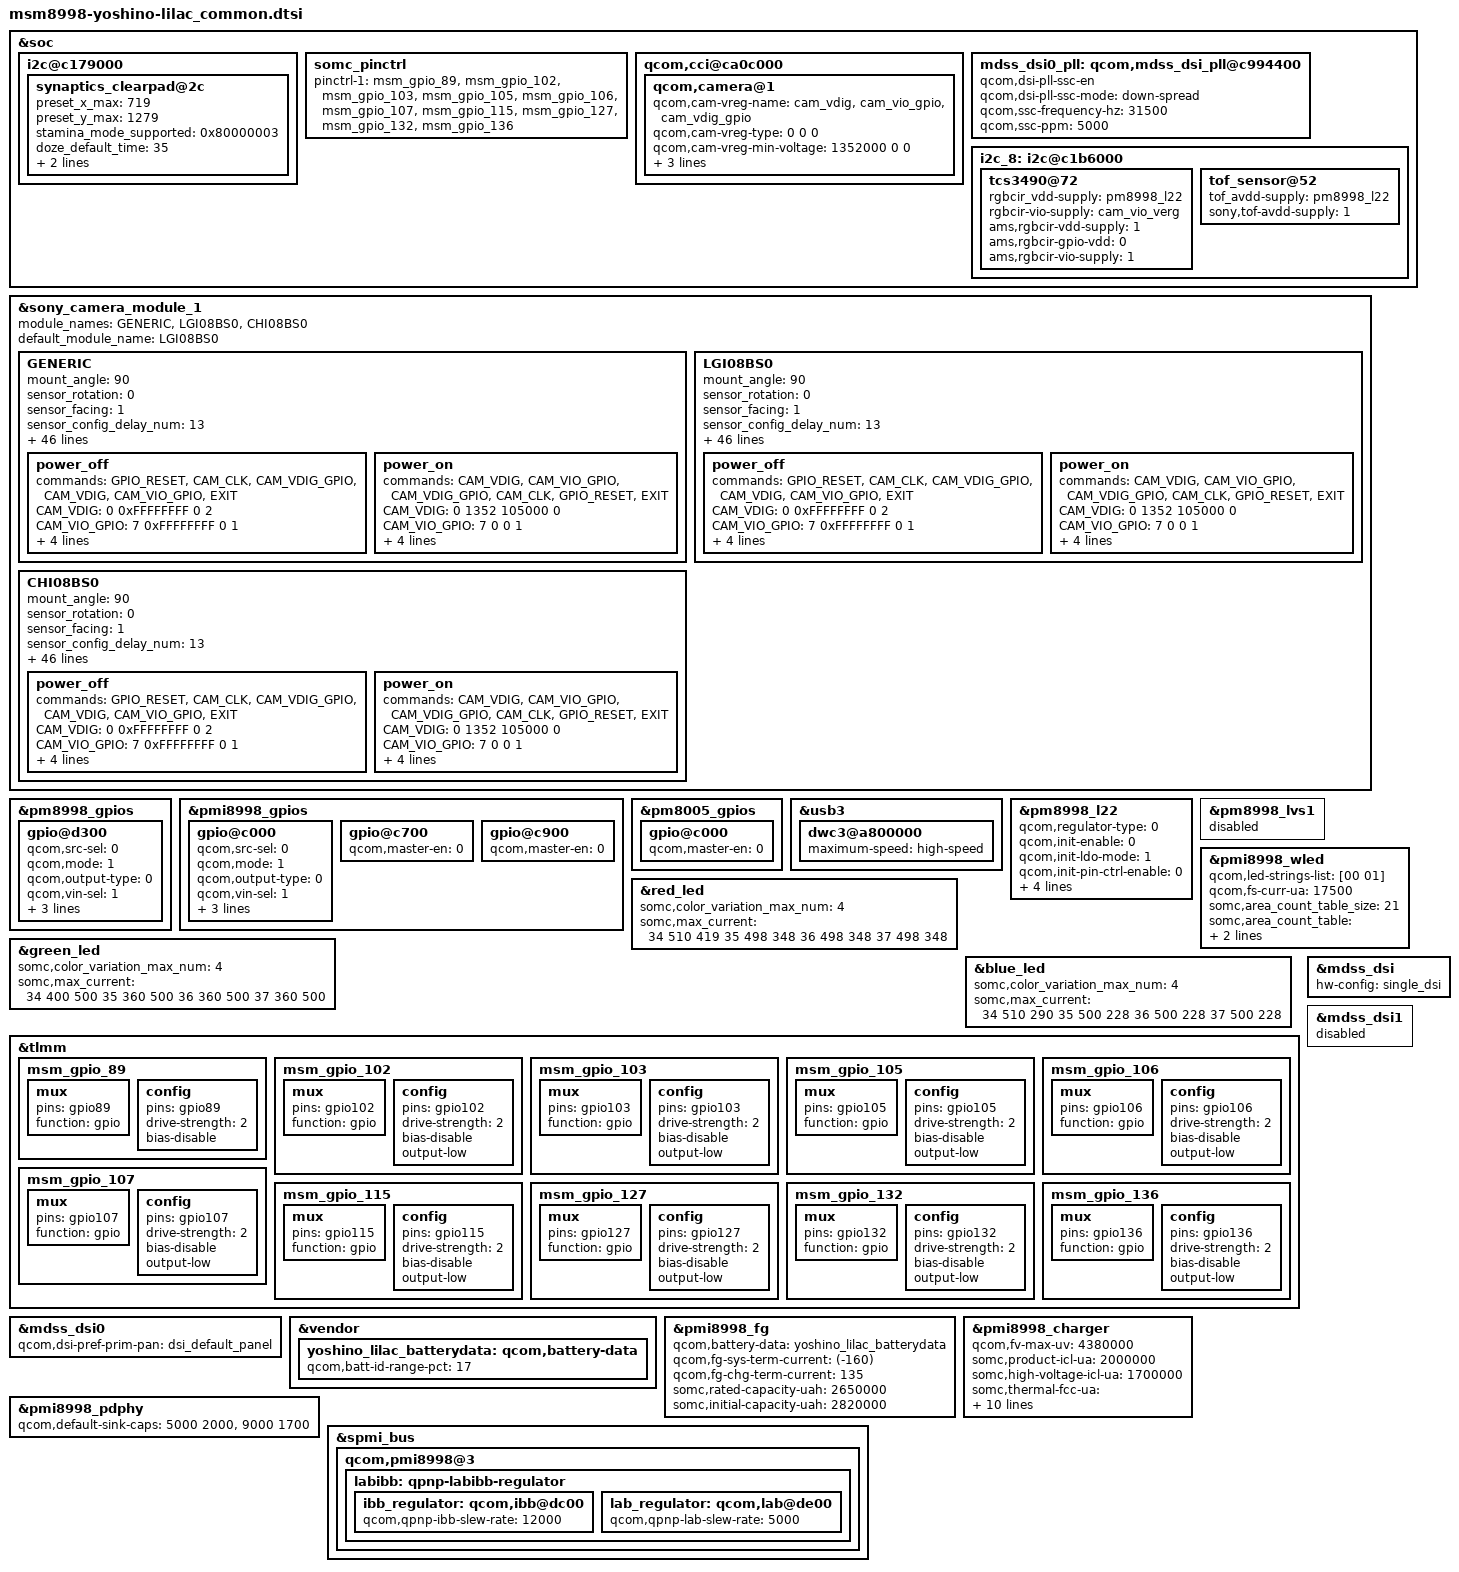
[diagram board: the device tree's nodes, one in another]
/* arch/arm64/boot/dts/qcom/msm8998-lilac_common.dtsi
 *
 * This program is free software; you can redistribute it and/or modify
 * it under the terms of the GNU General Public License version 2 and
 * only version 2 as published by the Free Software Foundation.
 *
 * This program is distributed in the hope that it will be useful,
 * but WITHOUT ANY WARRANTY; without even the implied warranty of
 * MERCHANTABILITY or FITNESS FOR A PARTICULAR PURPOSE.  See the
 * GNU General Public License for more details.
 */
/*
 * Copyright (C) 2016 Sony Mobile Communications Inc.
 *
 * This program is free software; you can redistribute it and/or modify
 * it under the terms of the GNU General Public License version 2, as
 * published by the Free Software Foundation.
 */

#include "msm8998-yoshino-common.dtsi"
#include "dsi-panel-lilac.dtsi"

&soc {
	/* I2C: BLSP5 */
	i2c@c179000 { /* BLSP1 QUP5 */
		synaptics_clearpad@2c {
			preset_x_max = <719>;
			preset_y_max = <1279>;

			/* Stamina Mode */
			stamina_mode_supported = <0x80000003>;

			/* F01_RMI_CTRL05: Doze Holdoff */
			doze_default_time = <35>;
			doze_glove_mode_time = <35>;
			doze_cover_mode_time = <35>;
		};
	};

	somc_pinctrl: somc_pinctrl {
		pinctrl-1 = <&msm_gpio_89 &msm_gpio_102 &msm_gpio_103 &msm_gpio_105 &msm_gpio_106
			     &msm_gpio_107 &msm_gpio_115 &msm_gpio_127 &msm_gpio_132 &msm_gpio_136>;
	};

	qcom,cci@ca0c000 {
		qcom,camera@1 {
			/delete-property/ cam_vio-supply;
			/delete-property/ cam_vaf-supply;
			qcom,cam-vreg-name = "cam_vdig", "cam_vio_gpio", "cam_vdig_gpio";
			qcom,cam-vreg-type = <0 0 0>;
			qcom,cam-vreg-min-voltage = <1352000 0 0>;
			qcom,cam-vreg-max-voltage = <1352000 0 0>;
			qcom,cam-vreg-op-mode = <105000 0 0>;
			sony,eeprom_type = <2>;
		};
	};

	mdss_dsi0_pll: qcom,mdss_dsi_pll@c994400 {
		qcom,dsi-pll-ssc-en;
		qcom,dsi-pll-ssc-mode = "down-spread";
		qcom,ssc-frequency-hz = <31500>;
		qcom,ssc-ppm = <5000>;
	};
	/* I2C : BLSP8 */
	i2c_8: i2c@c1b6000 { /* BLSP2 QUP2 */
		tcs3490@72 {
			rgbcir_vdd-supply = <&pm8998_l22>;
			rgbcir-vio-supply = <&cam_vio_verg>;
			ams,rgbcir-vdd-supply = <1>;
			ams,rgbcir-gpio-vdd = <0>;
			ams,rgbcir-vio-supply = <1>;
		};
		tof_sensor@52 {
			tof_avdd-supply = <&pm8998_l22>;
			sony,tof-avdd-supply = <1>;
		};
	};
};

&sony_camera_module_1 {
	module_names = "GENERIC", "LGI08BS0", "CHI08BS0";
	default_module_name = "LGI08BS0";
	/delete-node/ SOI13BS1;
	/delete-node/ SEM13BS1;

	GENERIC {
		mount_angle = <90>;
		sensor_rotation = <0>;
		sensor_facing = <1>;
		sensor_config_delay_num = <13>;
		sensor_config_delay = <3 3 3 3 3 3 3 3 3 3 3 3 3>;
		temperature_check_skip_num = <0>;
		total_pixel_number_w = <3296>;
		total_pixel_number_h = <2528>;
		active_pixel_number_x = <8>;
		active_pixel_number_y = <8>;
		active_pixel_number_w = <3280>;
		active_pixel_number_h = <2464>;
		min_focus_distance = <0>;
		hyper_focal_distance = <715>;
		diagonal_len = "4.595";
		unit_cell_size_w = "1.12";
		unit_cell_size_h = "1.12";
		min_f_number = "2.4";
		max_f_number = "2.4";
		min_focus_pos = <1>;
		max_focus_pos = <1024>;
		min_focus_dac = <0x0000>;
		max_focus_dac = <0x03FF>;
		focus_inf_range_offset = <0x24>;
		focus_macro_range_offset = <0x24>;
		focus_lens_stroke_inf_to_1m = <0x09>;
		focus_lens_stroke_1m_to_macro = <0x55>;
		focus_lens_stroke_inf_to_macro = <0x5E>;
		focus_calc_type = <0x01>;
		focus_wob_time = <0>;
		has_3a = <0>;
		has_focus_actuator = <0>;
		need_standby_af = <0>;
		i2c_freq_mode = <1>;
		has_pdaf = <0>;
		has_rs = <1>;
		has_multi_output = <0>;
		has_super_slow = <0>;
		has_sub_sensor = <0>;
		has_aube = <0>;
		has_flicker_detector = <0>;
		has_hdr = <0>;
		has_seamless_mode_change = <0>;
		has_gph = <0>;
		pdaf_free_area_num = <0>;
		pdaf_fixed_area_size_w = <0>;
		pdaf_fixed_area_size_h = <0>;
		pll_num = <26>;
		pll = <1134 1134 1134 1134 1134 1134 1134 1134 1134 1134 1134 1134 1134 1134 1134 1134 1134 1134 1134 1134 1134 1134 1134 1134 1134 1134>;
		power_off {
			commands =
				"GPIO_RESET",
				"CAM_CLK",
				"CAM_VDIG_GPIO",
				"CAM_VDIG",
				"CAM_VIO_GPIO",
				"EXIT";
			CAM_VDIG = <0 0xFFFFFFFF 0 2>;
			/delete-property/ CAM_VIO;
			/delete-property/ CAM_VAF;
			CAM_VIO_GPIO = <7 0xFFFFFFFF 0 1>;
			GPIO_RESET = <5 0x0 0 5>;
			CAM_VDIG_GPIO = <6 0xFFFFFFFF 0 5>;
			CAM_CLK = <10 0xFFFFFFFF 0 0>;
			EXIT = <12 0x0 0 0>;
		};
		power_on {
			commands =
				"CAM_VDIG",
				"CAM_VIO_GPIO",
				"CAM_VDIG_GPIO",
				"CAM_CLK",
				"GPIO_RESET",
				"EXIT";
			CAM_VDIG = <0 1352 105000 0>;
			/delete-property/ CAM_VIO;
			/delete-property/ CAM_VAF;
			CAM_VIO_GPIO = <7 0 0 1>;
			GPIO_RESET = <5 1 0 1>;
			CAM_VDIG_GPIO = <6 0 0 1>;
			CAM_CLK = <10 0 0 1>;
			EXIT = <12 0x0 0 0>;
		};
	};
	LGI08BS0 {
		mount_angle = <90>;
		sensor_rotation = <0>;
		sensor_facing = <1>;
		sensor_config_delay_num = <13>;
		sensor_config_delay = <3 3 3 3 3 3 3 3 3 3 3 3 3>;
		temperature_check_skip_num = <0>;
		total_pixel_number_w = <3296>;
		total_pixel_number_h = <2528>;
		active_pixel_number_x = <8>;
		active_pixel_number_y = <8>;
		active_pixel_number_w = <3280>;
		active_pixel_number_h = <2464>;
		min_focus_distance = <0>;
		hyper_focal_distance = <715>;
		diagonal_len = "4.595";
		unit_cell_size_w = "1.12";
		unit_cell_size_h = "1.12";
		min_f_number = "2.4";
		max_f_number = "2.4";
		min_focus_pos = <1>;
		max_focus_pos = <1024>;
		min_focus_dac = <0x0000>;
		max_focus_dac = <0x03FF>;
		focus_inf_range_offset = <0x24>;
		focus_macro_range_offset = <0x24>;
		focus_lens_stroke_inf_to_1m = <0x09>;
		focus_lens_stroke_1m_to_macro = <0x55>;
		focus_lens_stroke_inf_to_macro = <0x5E>;
		focus_calc_type = <0x01>;
		focus_wob_time = <0>;
		has_3a = <0>;
		has_focus_actuator = <0>;
		need_standby_af = <0>;
		i2c_freq_mode = <1>;
		has_pdaf = <0>;
		has_rs = <1>;
		has_multi_output = <0>;
		has_super_slow = <0>;
		has_sub_sensor = <0>;
		has_aube = <0>;
		has_flicker_detector = <0>;
		has_hdr = <0>;
		has_seamless_mode_change = <0>;
		has_gph = <0>;
		pdaf_free_area_num = <0>;
		pdaf_fixed_area_size_w = <0>;
		pdaf_fixed_area_size_h = <0>;
		pll_num = <26>;
		pll = <1134 1134 1134 1134 1134 1134 1134 1134 1134 1134 1134 1134 1134 1134 1134 1134 1134 1134 1134 1134 1134 1134 1134 1134 1134 1134>;
		power_off {
			commands =
				"GPIO_RESET",
				"CAM_CLK",
				"CAM_VDIG_GPIO",
				"CAM_VDIG",
				"CAM_VIO_GPIO",
				"EXIT";
			CAM_VDIG = <0 0xFFFFFFFF 0 2>;
			CAM_VIO_GPIO = <7 0xFFFFFFFF 0 1>;
			GPIO_RESET = <5 0x0 0 5>;
			CAM_VDIG_GPIO = <6 0xFFFFFFFF 0 5>;
			CAM_CLK = <10 0xFFFFFFFF 0 0>;
			EXIT = <12 0x0 0 0>;
		};
		power_on {
			commands =
				"CAM_VDIG",
				"CAM_VIO_GPIO",
				"CAM_VDIG_GPIO",
				"CAM_CLK",
				"GPIO_RESET",
				"EXIT";
			CAM_VDIG = <0 1352 105000 0>;
			CAM_VIO_GPIO = <7 0 0 1>;
			GPIO_RESET = <5 1 0 1>;
			CAM_VDIG_GPIO = <6 0 0 1>;
			CAM_CLK = <10 0 0 1>;
			EXIT = <12 0x0 0 0>;
		};
	};
	CHI08BS0 {
		mount_angle = <90>;
		sensor_rotation = <0>;
		sensor_facing = <1>;
		sensor_config_delay_num = <13>;
		sensor_config_delay = <3 3 3 3 3 3 3 3 3 3 3 3 3>;
		temperature_check_skip_num = <0>;
		total_pixel_number_w = <3296>;
		total_pixel_number_h = <2528>;
		active_pixel_number_x = <8>;
		active_pixel_number_y = <8>;
		active_pixel_number_w = <3280>;
		active_pixel_number_h = <2464>;
		min_focus_distance = <0>;
		hyper_focal_distance = <715>;
		diagonal_len = "4.595";
		unit_cell_size_w = "1.12";
		unit_cell_size_h = "1.12";
		min_f_number = "2.4";
		max_f_number = "2.4";
		min_focus_pos = <1>;
		max_focus_pos = <1024>;
		min_focus_dac = <0x0000>;
		max_focus_dac = <0x03FF>;
		focus_inf_range_offset = <0x24>;
		focus_macro_range_offset = <0x24>;
		focus_lens_stroke_inf_to_1m = <0x09>;
		focus_lens_stroke_1m_to_macro = <0x55>;
		focus_lens_stroke_inf_to_macro = <0x5E>;
		focus_calc_type = <0x01>;
		focus_wob_time = <0>;
		has_3a = <0>;
		has_focus_actuator = <0>;
		need_standby_af = <0>;
		i2c_freq_mode = <1>;
		has_pdaf = <0>;
		has_rs = <1>;
		has_multi_output = <0>;
		has_super_slow = <0>;
		has_sub_sensor = <0>;
		has_aube = <0>;
		has_flicker_detector = <0>;
		has_hdr = <0>;
		has_seamless_mode_change = <0>;
		has_gph = <0>;
		pdaf_free_area_num = <0>;
		pdaf_fixed_area_size_w = <0>;
		pdaf_fixed_area_size_h = <0>;
		pll_num = <26>;
		pll = <1134 1134 1134 1134 1134 1134 1134 1134 1134 1134 1134 1134 1134 1134 1134 1134 1134 1134 1134 1134 1134 1134 1134 1134 1134 1134>;
		power_off {
			commands =
				"GPIO_RESET",
				"CAM_CLK",
				"CAM_VDIG_GPIO",
				"CAM_VDIG",
				"CAM_VIO_GPIO",
				"EXIT";
			CAM_VDIG = <0 0xFFFFFFFF 0 2>;
			CAM_VIO_GPIO = <7 0xFFFFFFFF 0 1>;
			GPIO_RESET = <5 0x0 0 5>;
			CAM_VDIG_GPIO = <6 0xFFFFFFFF 0 5>;
			CAM_CLK = <10 0xFFFFFFFF 0 0>;
			EXIT = <12 0x0 0 0>;
		};
		power_on {
			commands =
				"CAM_VDIG",
				"CAM_VIO_GPIO",
				"CAM_VDIG_GPIO",
				"CAM_CLK",
				"GPIO_RESET",
				"EXIT";
			CAM_VDIG = <0 1352 105000 0>;
			CAM_VIO_GPIO = <7 0 0 1>;
			GPIO_RESET = <5 1 0 1>;
			CAM_VDIG_GPIO = <6 0 0 1>;
			CAM_CLK = <10 0 0 1>;
			EXIT = <12 0x0 0 0>;
		};
	};
};

&pm8998_gpios {
	/* GPIO_20: DTV_PWR_EN */
	gpio@d300 {
		qcom,src-sel = <0>;             /* GPIO */
		qcom,mode = <1>;                /* Out */
		qcom,output-type = <0>;         /* CMOS */
		qcom,vin-sel = <1>;             /* 1.8V */
		qcom,out-strength = <1>;        /* Low */
		qcom,invert = <0>;              /* Low */
		qcom,master-en = <1>;           /* Enable */
		status = "okay";
	};
};

&pmi8998_gpios {
	/* GPIO_1: MAIN_CAM_PWR_IO_EN */
	gpio@c000 {
		qcom,src-sel = <0>;             /* GPIO */
		qcom,mode = <1>;                /* Out */
		qcom,output-type = <0>;         /* CMOS */
		qcom,vin-sel = <1>;             /* 1.8V */
		qcom,out-strength = <1>;        /* Low */
		qcom,invert = <0>;              /* Low */
		qcom,master-en = <1>;           /* Enable */
		status = "okay";
	};

	/* GPIO_8: NC */
	gpio@c700 {
		qcom,master-en = <0>;           /* Disable */
		status = "okay";
	};

	/* GPIO_10: NC */
	gpio@c900 {
		qcom,master-en = <0>;           /* Disable */
		status = "okay";
	};
};

&pm8005_gpios {
	/* GPIO_1: NC */
	gpio@c000 {
		qcom,master-en = <0>;           /* Disable */
		status = "okay";
	};
};

&usb3 {
	dwc3@a800000 {
		maximum-speed = "high-speed";
	};
};

/* Regulator config */
&pm8998_l22 {
	qcom,regulator-type = <0>;     /* LDO */
	qcom,init-enable = <0>;
	qcom,init-ldo-mode = <1>;
	qcom,init-pin-ctrl-enable = <0>;
	qcom,init-pin-ctrl-mode = <0>;
	regulator-min-microvolt = <2800000>;
	regulator-max-microvolt = <2800000>;
	qcom,init-voltage = <2800000>;
	status = "okay";
};

&pm8998_lvs1 {
	status = "disabled";
};

&pmi8998_wled {
	qcom,led-strings-list = [00 01];
	qcom,fs-curr-ua = <17500>;
	somc,area_count_table_size = <21>;
	somc,area_count_table = <0 137 273 410 546 683 819 956
				1092 1229 1365 1638 1911 2184 2457
				2730 3003 3276 3549 3822 4095>;
	somc,init-br-ua = <8500>;
};

&red_led {
	somc,color_variation_max_num = <4>;
	somc,max_current = <
		34 510 419
		35 498 348
		36 498 348
		37 498 348>;
};

&green_led {
	somc,color_variation_max_num = <4>;
	somc,max_current = <
		34 400 500
		35 360 500
		36 360 500
		37 360 500>;
};

&blue_led {
	somc,color_variation_max_num = <4>;
	somc,max_current = <
		34 510 290
		35 500 228
		36 500 228
		37 500 228>;
};

&tlmm {
	/* GPIO_89 : TS_RESET_N */
	msm_gpio_89: msm_gpio_89 {
		mux {
			pins = "gpio89";
			function = "gpio";
		};

		config {
			pins = "gpio89";
			drive-strength = <2>;
			bias-disable;
		};
	};

	/* GPIO_102 : NC */
	msm_gpio_102: msm_gpio_102{
		mux {
			pins = "gpio102";
			function = "gpio";
		};

		config {
			pins = "gpio102";
			drive-strength = <2>;
			bias-disable;
			output-low;
		};
	};

	/* GPIO_103 : NC */
	msm_gpio_103: msm_gpio_103{
		mux {
			pins = "gpio103";
			function = "gpio";
		};

		config {
			pins = "gpio103";
			drive-strength = <2>;
			bias-disable;
			output-low;
		};
	};

	/* GPIO_105 : NC */
	msm_gpio_105: msm_gpio_105{
		mux {
			pins = "gpio105";
			function = "gpio";
		};

		config {
			pins = "gpio105";
			drive-strength = <2>;
			bias-disable;
			output-low;
		};
	};

	/* GPIO_106 : NC */
	msm_gpio_106: msm_gpio_106{
		mux {
			pins = "gpio106";
			function = "gpio";
		};

		config {
			pins = "gpio106";
			drive-strength = <2>;
			bias-disable;
			output-low;
		};
	};

	/* GPIO_107 : NC */
	msm_gpio_107: msm_gpio_107{
		mux {
			pins = "gpio107";
			function = "gpio";
		};

		config {
			pins = "gpio107";
			drive-strength = <2>;
			bias-disable;
			output-low;
		};
	};

	/* GPIO_115 : NC */
	msm_gpio_115: msm_gpio_115{
		mux {
			pins = "gpio115";
			function = "gpio";
		};

		config {
			pins = "gpio115";
			drive-strength = <2>;
			bias-disable;
			output-low;
		};
	};

	/* GPIO_127 : NC */
	msm_gpio_127: msm_gpio_127{
		mux {
			pins = "gpio127";
			function = "gpio";
		};

		config {
			pins = "gpio127";
			drive-strength = <2>;
			bias-disable;
			output-low;
		};
	};

	/* GPIO_132: NC */
	msm_gpio_132: msm_gpio_132{
		mux {
			pins = "gpio132";
			function = "gpio";
		};

		config {
			pins = "gpio132";
			drive-strength = <2>;
			bias-disable;
			output-low;
		};
	};

	/* GPIO_136: NC */
	msm_gpio_136: msm_gpio_136{
		mux {
			pins = "gpio136";
			function = "gpio";
		};

		config {
			pins = "gpio136";
			drive-strength = <2>;
			bias-disable;
			output-low;
		};
	};
};

&mdss_dsi {
	hw-config = "single_dsi";
};

&mdss_dsi0 {
	qcom,dsi-pref-prim-pan = <&dsi_default_panel>;
};

&mdss_dsi1 {
	status = "disabled";
	/delete-property/ qcom,dsi-pref-prim-pan;
};

&vendor {
	yoshino_lilac_batterydata: qcom,battery-data {
		qcom,batt-id-range-pct = <17>;
		#include "fg-gen3-batterydata-lilac-send-4380mv-2729mah.dtsi"
		#include "fg-gen3-batterydata-lilac-send-4357mv-2688mah.dtsi"
		#include "fg-gen3-batterydata-lilac-send-4335mv-2647mah.dtsi"
		#include "fg-gen3-batterydata-lilac-send-4297mv-2539mah.dtsi"
		#include "fg-gen3-batterydata-lilac-send-4245mv-2425mah.dtsi"
	};
};

&pmi8998_fg {
	qcom,battery-data = <&yoshino_lilac_batterydata>;
	qcom,fg-sys-term-current = <(-160)>;
	qcom,fg-chg-term-current = <135>;
	somc,rated-capacity-uah = <2650000>;
	somc,initial-capacity-uah = <2820000>;
};

&pmi8998_charger {
	qcom,fv-max-uv = <4380000>;
	somc,product-icl-ua = <2000000>;
	somc,high-voltage-icl-ua = <1700000>;
	somc,thermal-fcc-ua = <2025000 2000000 1950000
				1800000 1500000 1300000
				1300000 1000000 800000
				700000 700000 500000
				300000 100000 0>;
	somc,thermal-lo-volt-icl-ua = <2000000 1500000 1500000
					1500000 1300000 1100000
					1100000 1000000 900000
					900000 900000 500000
					200000 100000 0>;
	somc,thermal-hi-volt-icl-ua = <1700000 1700000 1700000
					1700000 1500000 1500000
					1000000 1000000 1000000
					1000000 600000 500000
					200000 100000 0>;
	somc,jeita-use-aux-therm;
	somc,jeita-aux-thresh-hot = <530>;
	somc,jeita-aux-thresh-warm = <430>;
	somc,jeita-warm-fcc-ua = <800000>;
	somc,jeita-cool-fcc-ua = <800000>;
};

&pmi8998_pdphy {
	qcom,default-sink-caps = <5000 2000>, /* 5V @ 2A */
				 <9000 1700>; /* 9V @ 1.7A */
};

&spmi_bus {
	qcom,pmi8998@3 {
		labibb: qpnp-labibb-regulator {
			ibb_regulator: qcom,ibb@dc00 {
				qcom,qpnp-ibb-slew-rate = <12000>;
			};
			lab_regulator: qcom,lab@de00 {
				qcom,qpnp-lab-slew-rate = <5000>;
			};
		};
	};
};
